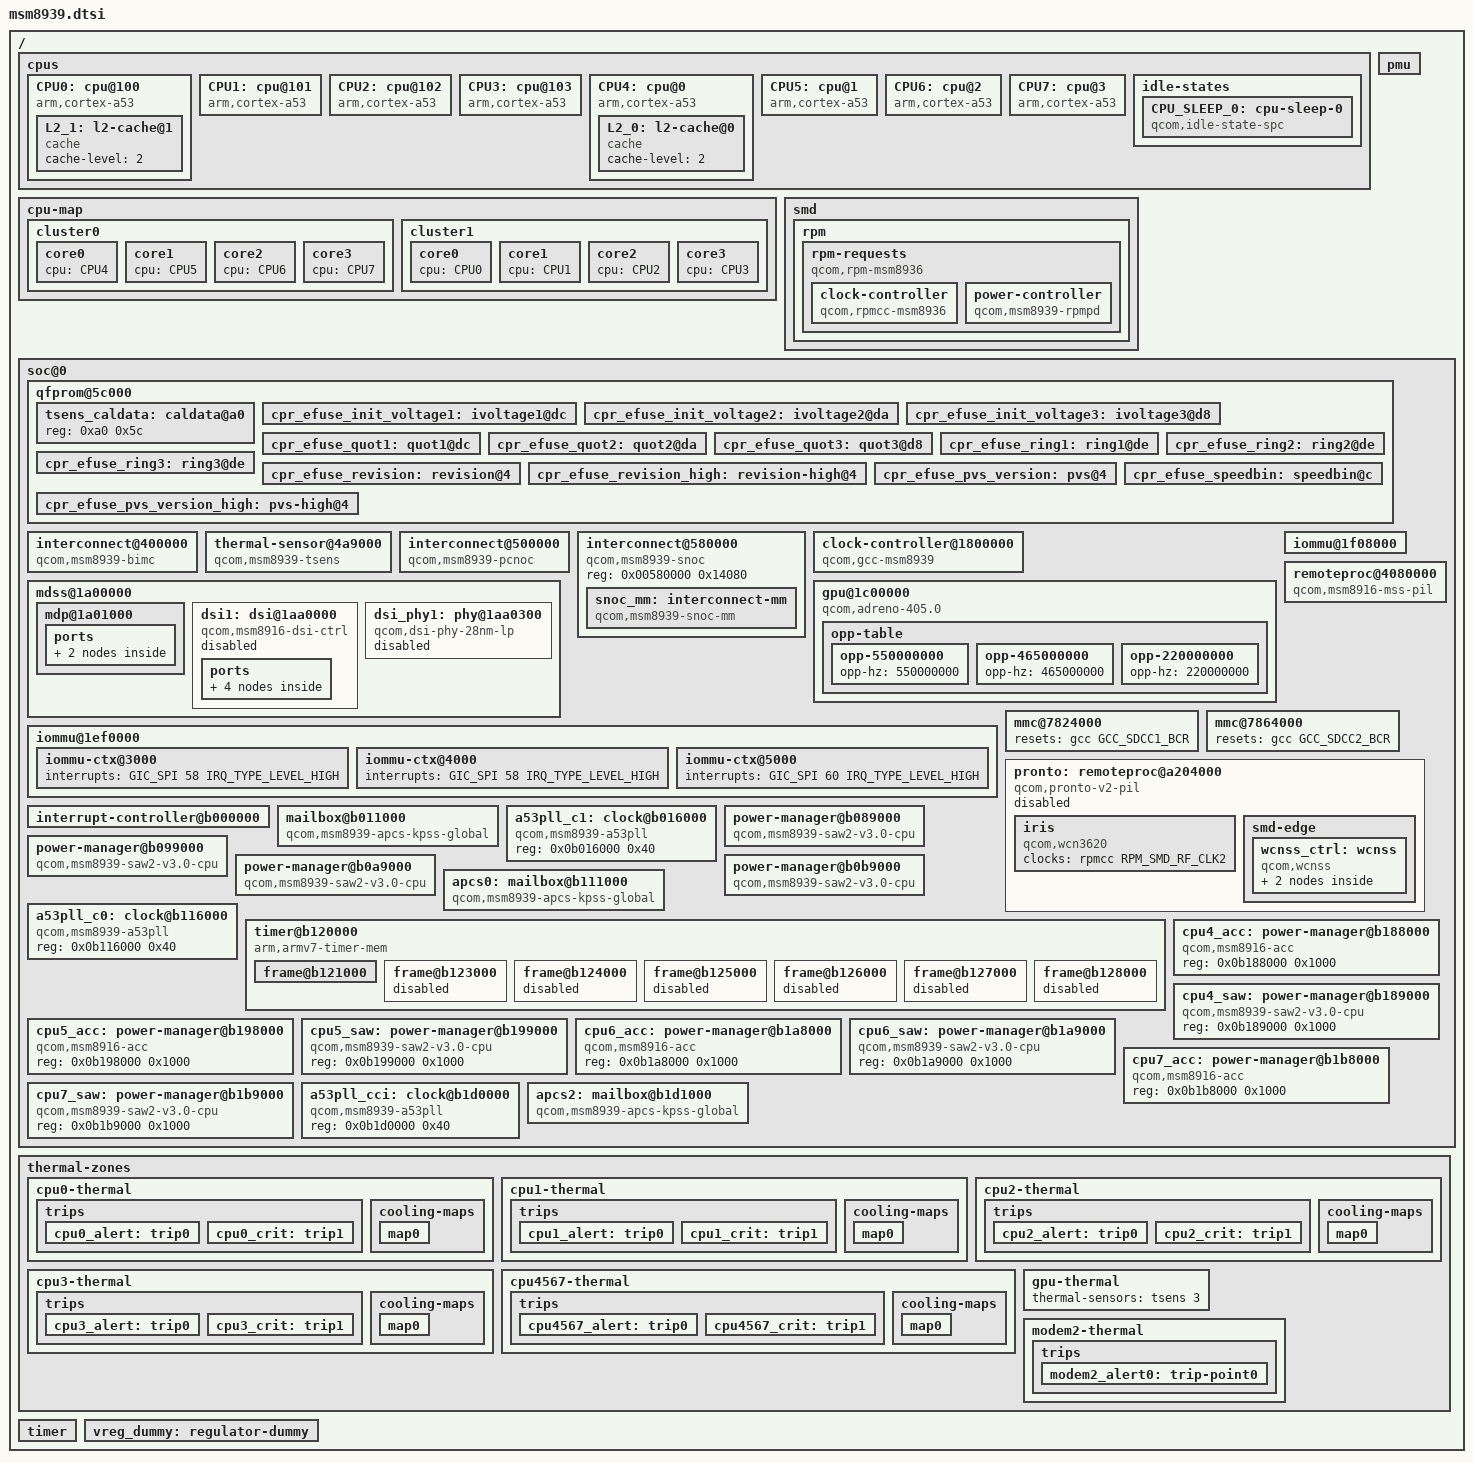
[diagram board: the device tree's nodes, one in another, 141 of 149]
// SPDX-License-Identifier: GPL-2.0-only
/*
 * Copyright (c) 2013-2015, The Linux Foundation. All rights reserved.
 */

#include <dt-bindings/clock/qcom,gcc-msm8939.h>
#include <dt-bindings/interconnect/qcom,msm8939.h>
#include <dt-bindings/reset/qcom,gcc-msm8939.h>

#include "msm8916-common.dtsi"

/ {
	cpus {
		#address-cells = <1>;
		#size-cells = <0>;

		CPU0: cpu@100 {
			device_type = "cpu";
			compatible = "arm,cortex-a53";
			reg = <0x100>;
			next-level-cache = <&L2_1>;
			enable-method = "spin-table";
			clocks = <&apcs>;
			#cooling-cells = <2>;
			power-domains = <&vreg_dummy>;
			power-domain-names = "cpr";
			qcom,acc = <&cpu0_acc>;
			qcom,saw = <&cpu0_saw>;
			cpu-idle-states = <&CPU_SLEEP_0>;

			L2_1: l2-cache@1 {
				compatible = "cache";
				cache-level = <2>;
			};
		};

		CPU1: cpu@101 {
			device_type = "cpu";
			compatible = "arm,cortex-a53";
			reg = <0x101>;
			next-level-cache = <&L2_1>;
			enable-method = "spin-table";
			clocks = <&apcs>;
			#cooling-cells = <2>;
			power-domains = <&vreg_dummy>;
			power-domain-names = "cpr";
			qcom,acc = <&cpu1_acc>;
			qcom,saw = <&cpu1_saw>;
			cpu-idle-states = <&CPU_SLEEP_0>;
		};

		CPU2: cpu@102 {
			device_type = "cpu";
			compatible = "arm,cortex-a53";
			reg = <0x102>;
			next-level-cache = <&L2_1>;
			enable-method = "spin-table";
			clocks = <&apcs>;
			#cooling-cells = <2>;
			power-domains = <&vreg_dummy>;
			power-domain-names = "cpr";
			qcom,acc = <&cpu2_acc>;
			qcom,saw = <&cpu2_saw>;
			cpu-idle-states = <&CPU_SLEEP_0>;
		};

		CPU3: cpu@103 {
			device_type = "cpu";
			compatible = "arm,cortex-a53";
			reg = <0x103>;
			next-level-cache = <&L2_1>;
			enable-method = "spin-table";
			clocks = <&apcs>;
			#cooling-cells = <2>;
			power-domains = <&vreg_dummy>;
			power-domain-names = "cpr";
			qcom,acc = <&cpu3_acc>;
			qcom,saw = <&cpu3_saw>;
			cpu-idle-states = <&CPU_SLEEP_0>;
		};

		CPU4: cpu@0 {
			device_type = "cpu";
			compatible = "arm,cortex-a53";
			reg = <0x0>;
			next-level-cache = <&L2_0>;
			enable-method = "spin-table";
			clocks = <&apcs0>;
			#cooling-cells = <2>;
			power-domains = <&vreg_dummy>;
			power-domain-names = "cpr";
			qcom,acc = <&cpu4_acc>;
			qcom,saw = <&cpu4_saw>;
			cpu-idle-states = <&CPU_SLEEP_0>;

			L2_0: l2-cache@0 {
				compatible = "cache";
				cache-level = <2>;
			};
		};

		CPU5: cpu@1 {
			device_type = "cpu";
			compatible = "arm,cortex-a53";
			reg = <0x1>;
			next-level-cache = <&L2_0>;
			enable-method = "spin-table";
			clocks = <&apcs0>;
			#cooling-cells = <2>;
			power-domains = <&vreg_dummy>;
			power-domain-names = "cpr";
			qcom,acc = <&cpu5_acc>;
			qcom,saw = <&cpu5_saw>;
			cpu-idle-states = <&CPU_SLEEP_0>;
		};

		CPU6: cpu@2 {
			device_type = "cpu";
			compatible = "arm,cortex-a53";
			reg = <0x2>;
			next-level-cache = <&L2_0>;
			enable-method = "spin-table";
			clocks = <&apcs0>;
			#cooling-cells = <2>;
			power-domains = <&vreg_dummy>;
			power-domain-names = "cpr";
			qcom,acc = <&cpu6_acc>;
			qcom,saw = <&cpu6_saw>;
			cpu-idle-states = <&CPU_SLEEP_0>;
		};

		CPU7: cpu@3 {
			device_type = "cpu";
			compatible = "arm,cortex-a53";
			reg = <0x3>;
			next-level-cache = <&L2_0>;
			enable-method = "spin-table";
			clocks = <&apcs0>;
			#cooling-cells = <2>;
			power-domains = <&vreg_dummy>;
			power-domain-names = "cpr";
			qcom,acc = <&cpu7_acc>;
			qcom,saw = <&cpu7_saw>;
			cpu-idle-states = <&CPU_SLEEP_0>;
		};

		idle-states {
			CPU_SLEEP_0: cpu-sleep-0 {
				compatible ="qcom,idle-state-spc", "arm,idle-state";
				entry-latency-us = <130>;
				exit-latency-us = <150>;
				min-residency-us = <2000>;
				local-timer-stop;
			};
		};
	};

	/*
	 * MSM8939 has a big.LITTLE heterogeneous computing architecture,
	 * consisting of two clusters of four ARM Cortex-A53s each. The
	 * LITTLE cluster runs at 1.0-1.2GHz, and the big cluster runs
	 * at 1.5-1.7GHz.
	 *
	 * The enable method used here is spin-table which presupposes use
	 * of a 2nd stage boot shim such as lk2nd to have installed a
	 * spin-table, the downstream non-psci/non-spin-table method that
	 * default msm8916/msm8936/msm8939 will not be supported upstream.
	 */
	cpu-map {
		/* LITTLE (efficiency) cluster */
		cluster0 {
			core0 {
				cpu = <&CPU4>;
			};

			core1 {
				cpu = <&CPU5>;
			};

			core2 {
				cpu = <&CPU6>;
			};

			core3 {
				cpu = <&CPU7>;
			};
		};

		/*
		 * big (performance) cluster
		 * Boot CPU is cluster 1 core 0
		 */
		cluster1 {
			core0 {
				cpu = <&CPU0>;
			};

			core1 {
				cpu = <&CPU1>;
			};

			core2 {
				cpu = <&CPU2>;
			};

			core3 {
				cpu = <&CPU3>;
			};
		};
	};

	pmu {
		interrupts = <GIC_PPI 7 (GIC_CPU_MASK_SIMPLE(8) | IRQ_TYPE_LEVEL_HIGH)>;
	};

	smd {
		rpm {
			rpm-requests {
				compatible = "qcom,rpm-msm8936";

				clock-controller {
					compatible = "qcom,rpmcc-msm8936", "qcom,rpmcc";
				};

				power-controller {
					compatible = "qcom,msm8939-rpmpd";
				};
			};
		};
	};

	soc@0 {
		qfprom@5c000 {
			tsens_caldata: caldata@a0 {
				reg = <0xa0 0x5c>;
			};

			cpr_efuse_init_voltage1: ivoltage1@dc {
				reg = <0xdc 0x4>;
				bits = <4 6>;
			};

			cpr_efuse_init_voltage2: ivoltage2@da {
				reg = <0xda 0x4>;
				bits = <2 6>;
			};

			cpr_efuse_init_voltage3: ivoltage3@d8 {
				reg = <0xd8 0x4>;
				bits = <0 6>;
			};

			cpr_efuse_quot1: quot1@dc {
				reg = <0xdd 0x8>;
				bits = <2 12>;
			};

			cpr_efuse_quot2: quot2@da {
				reg = <0xdb 0x8>;
				bits = <0x0 12>;
			};

			cpr_efuse_quot3: quot3@d8 {
				reg = <0xd8 0x8>;
				bits = <6 12>;
			};

			cpr_efuse_ring1: ring1@de {
				reg = <0xde 0x4>;
				bits = <6 3>;
			};

			cpr_efuse_ring2: ring2@de {
				reg = <0xde 0x4>;
				bits = <6 3>;
			};

			cpr_efuse_ring3: ring3@de {
				reg = <0xde 0x4>;
				bits = <6 3>;
			};

			cpr_efuse_revision: revision@4 {
				reg = <0x5 0x1>;
				bits = <5 1>;
			};

			cpr_efuse_revision_high: revision-high@4 {
				reg = <0x7 0x1>;
				bits = <0 1>;
			};

			cpr_efuse_pvs_version: pvs@4 {
				reg = <0x3 0x1>;
				bits = <5 1>;
			};

			cpr_efuse_pvs_version_high: pvs-high@4 {
				reg = <0x6 0x1>;
				bits = <2 2>;
			};

			cpr_efuse_speedbin: speedbin@c {
				reg = <0xc 0x1>;
				bits = <2 3>;
			};
		};

		interconnect@400000 {
			compatible = "qcom,msm8939-bimc";
		};

		thermal-sensor@4a9000 {
			compatible = "qcom,msm8939-tsens", "qcom,tsens-v0_1";
			nvmem-cells = <&tsens_caldata>;
			nvmem-cell-names = "calib";
			#qcom,sensors = <10>;
		};

		interconnect@500000 {
			compatible = "qcom,msm8939-pcnoc";
		};

		interconnect@580000 {
			compatible = "qcom,msm8939-snoc";
			reg = <0x00580000 0x14080>;

			snoc_mm: interconnect-mm {
				compatible = "qcom,msm8939-snoc-mm";
				clocks = <&rpmcc RPM_SMD_SYSMMNOC_CLK>,
					 <&rpmcc RPM_SMD_SYSMMNOC_A_CLK>;
				clock-names = "bus", "bus_a";
				#interconnect-cells = <1>;
			};
		};

		clock-controller@1800000 {
			compatible = "qcom,gcc-msm8939";
		};

		mdss@1a00000 {
			mdp@1a01000 {
				clocks = <&gcc GCC_MDSS_AHB_CLK>,
					 <&gcc GCC_MDSS_AXI_CLK>,
					 <&gcc GCC_MDSS_MDP_CLK>,
					 <&gcc GCC_MDSS_VSYNC_CLK>,
					 <&gcc GCC_MDP_TBU_CLK>,
					 <&gcc GCC_MDP_RT_TBU_CLK>;
				clock-names = "iface",
					      "bus",
					      "core",
					      "vsync",
					      "tbu",
					      "tbu_rt";

				ports {
					port@1 {
						reg = <1>;

						mdp5_intf2_out: endpoint {
							remote-endpoint = <&dsi1_in>;
						};
					};
				};
			};

			dsi1: dsi@1aa0000 {
				compatible = "qcom,msm8916-dsi-ctrl",
					     "qcom,mdss-dsi-ctrl";
				reg = <0x01aa0000 0x25c>;
				reg-names = "dsi_ctrl";

				interrupt-parent = <&mdss>;
				interrupts = <5>;

				assigned-clocks = <&gcc BYTE1_CLK_SRC>,
						  <&gcc PCLK1_CLK_SRC>;
				assigned-clock-parents = <&dsi_phy1 0>,
							 <&dsi_phy1 1>;

				clocks = <&gcc GCC_MDSS_MDP_CLK>,
					 <&gcc GCC_MDSS_AHB_CLK>,
					 <&gcc GCC_MDSS_AXI_CLK>,
					 <&gcc GCC_MDSS_BYTE1_CLK>,
					 <&gcc GCC_MDSS_PCLK1_CLK>,
					 <&gcc GCC_MDSS_ESC1_CLK>;
				clock-names = "mdp_core",
					      "iface",
					      "bus",
					      "byte",
					      "pixel",
					      "core";
				phys = <&dsi_phy1>;
				status = "disabled";

				ports {
					#address-cells = <1>;
					#size-cells = <0>;

					port@0 {
						reg = <0>;

						dsi1_in: endpoint {
							remote-endpoint = <&mdp5_intf2_out>;
						};
					};

					port@1 {
						reg = <1>;

						dsi1_out: endpoint {
						};
					};
				};
			};

			dsi_phy1: phy@1aa0300 {
				compatible = "qcom,dsi-phy-28nm-lp";
				reg = <0x01aa0300 0xd4>,
				      <0x01aa0500 0x280>,
				      <0x01aa0780 0x30>;
				reg-names = "dsi_pll",
					    "dsi_phy",
					    "dsi_phy_regulator";

				clocks = <&gcc GCC_MDSS_AHB_CLK>,
					 <&xo_board>;
				clock-names = "iface", "ref";

				#clock-cells = <1>;
				#phy-cells = <0>;
				status = "disabled";
			};
		};

		gpu@1c00000 {
			compatible = "qcom,adreno-405.0", "qcom,adreno";
			reg = <0x01c00000 0x10000>;
			reg-names = "kgsl_3d0_reg_memory";
			clocks = <&gcc GCC_OXILI_GFX3D_CLK>,
				 <&gcc GCC_OXILI_AHB_CLK>,
				 <&gcc GCC_OXILI_GMEM_CLK>,
				 <&gcc GCC_BIMC_GFX_CLK>,
				 <&gcc GCC_BIMC_GPU_CLK>,
				 <&gcc GFX3D_CLK_SRC>,
				 <&gcc GCC_OXILI_TIMER_CLK>;
			clock-names = "core",
				      "iface",
				      "mem",
				      "mem_iface",
				      "alt_mem_iface",
				      "gfx3d",
				      "rbbmtimer";

			opp-table {
				opp-550000000 {
					opp-hz = /bits/ 64 <550000000>;
				};

				opp-465000000 {
					opp-hz = /bits/ 64 <465000000>;
				};

				opp-220000000 {
					opp-hz = /bits/ 64 <220000000>;
				};
			};
		};

		iommu@1ef0000 {
			/* VFE */
			iommu-ctx@3000 {
				interrupts = <GIC_SPI 58 IRQ_TYPE_LEVEL_HIGH>;
			};

			/* MDP_0 */
			iommu-ctx@4000 {
				interrupts = <GIC_SPI 58 IRQ_TYPE_LEVEL_HIGH>;
			};

			/* VENUS_NS */
			iommu-ctx@5000 {
				interrupts = <GIC_SPI 60 IRQ_TYPE_LEVEL_HIGH>;
			};
		};

		iommu@1f08000 {
			clocks = <&gcc GCC_SMMU_CFG_CLK>,
				 <&gcc GCC_GFX_TCU_CLK>,
				 <&gcc GCC_GFX_TBU_CLK>;
			clock-names = "iface", "bus", "tbu";
		};

		remoteproc@4080000 {
			compatible = "qcom,msm8916-mss-pil", "qcom,q6v5-pil";
			power-domains = <&rpmpd MSM8939_VDDMDCX>,
					<&rpmpd MSM8939_VDDMX>;
		};

		mmc@7824000 {
			resets = <&gcc GCC_SDCC1_BCR>;
		};

		mmc@7864000 {
			resets = <&gcc GCC_SDCC2_BCR>;
		};

		pronto: remoteproc@a204000 {
			compatible = "qcom,pronto-v2-pil", "qcom,pronto";
			reg = <0x0a204000 0x2000>, <0x0a202000 0x1000>, <0x0a21b000 0x3000>;
			reg-names = "ccu", "dxe", "pmu";

			memory-region = <&wcnss_mem>;

			interrupts-extended = <&intc GIC_SPI 149 IRQ_TYPE_EDGE_RISING>,
					      <&wcnss_smp2p_in 0 IRQ_TYPE_EDGE_RISING>,
					      <&wcnss_smp2p_in 1 IRQ_TYPE_EDGE_RISING>,
					      <&wcnss_smp2p_in 2 IRQ_TYPE_EDGE_RISING>,
					      <&wcnss_smp2p_in 3 IRQ_TYPE_EDGE_RISING>;
			interrupt-names = "wdog", "fatal", "ready", "handover", "stop-ack";

			power-domains = <&rpmpd MSM8939_VDDCX>,
					<&rpmpd MSM8939_VDDMX_AO>;
			power-domain-names = "cx", "mx";

			qcom,smem-states = <&wcnss_smp2p_out 0>;
			qcom,smem-state-names = "stop";

			pinctrl-0 = <&wcnss_pin_a>;
			pinctrl-names = "default";

			status = "disabled";

			iris {
				compatible = "qcom,wcn3620";

				clocks = <&rpmcc RPM_SMD_RF_CLK2>;
				clock-names = "xo";
			};

			smd-edge {
				interrupts = <GIC_SPI 142 IRQ_TYPE_EDGE_RISING>;

				qcom,ipc = <&apcs 8 17>;
				qcom,smd-edge = <6>;
				qcom,remote-pid = <4>;

				label = "pronto";

				wcnss_ctrl: wcnss {
					compatible = "qcom,wcnss";
					qcom,smd-channels = "WCNSS_CTRL";

					qcom,mmio = <&pronto>;

					bluetooth {
						compatible = "qcom,wcnss-bt";
					};

					wifi {
						compatible = "qcom,wcnss-wlan";

						interrupts = <GIC_SPI 145 IRQ_TYPE_LEVEL_HIGH>,
							     <GIC_SPI 146 IRQ_TYPE_LEVEL_HIGH>;
						interrupt-names = "tx", "rx";

						qcom,smem-states = <&apps_smsm 10>, <&apps_smsm 9>;
						qcom,smem-state-names = "tx-enable", "tx-rings-empty";
					};
				};
			};
		};

		interrupt-controller@b000000 {
			interrupts = <GIC_PPI 0 (GIC_CPU_MASK_SIMPLE(8) | IRQ_TYPE_LEVEL_HIGH)>;
		};

		mailbox@b011000 {
			compatible = "qcom,msm8939-apcs-kpss-global", "syscon";
			clocks = <&a53pll_c1>, <&gcc GPLL0_VOTE>, <&xo_board>;
			clock-names = "pll", "aux", "ref";
			assigned-clocks = <&apcs2>;
			assigned-clock-rates = <297600000>;
		};

		a53pll_c1: clock@b016000 {
			compatible = "qcom,msm8939-a53pll";
			reg = <0x0b016000 0x40>;
			#clock-cells = <0>;
		};

		power-manager@b089000 {
			compatible = "qcom,msm8939-saw2-v3.0-cpu", "qcom,saw2";
		};

		power-manager@b099000 {
			compatible = "qcom,msm8939-saw2-v3.0-cpu", "qcom,saw2";
		};

		power-manager@b0a9000 {
			compatible = "qcom,msm8939-saw2-v3.0-cpu", "qcom,saw2";
		};

		power-manager@b0b9000 {
			compatible = "qcom,msm8939-saw2-v3.0-cpu", "qcom,saw2";
		};

		apcs0: mailbox@b111000 {
			compatible = "qcom,msm8939-apcs-kpss-global", "syscon";
			reg = <0x0b111000 0x1000>;
			clocks = <&a53pll_c0>, <&gcc GPLL0_VOTE>, <&xo_board>;
			clock-names = "pll", "aux", "ref";
			#clock-cells = <0>;
			#mbox-cells = <1>;
		};

		a53pll_c0: clock@b116000 {
			compatible = "qcom,msm8939-a53pll";
			reg = <0x0b116000 0x40>;
			#clock-cells = <0>;
		};

		timer@b120000 {
			compatible = "arm,armv7-timer-mem";
			reg = <0x0b120000 0x1000>;
			clock-frequency = <19200000>;
			#address-cells = <1>;
			#size-cells = <1>;
			ranges;

			frame@b121000 {
				frame-number = <0>;
				interrupts = <GIC_SPI 8 IRQ_TYPE_LEVEL_HIGH>,
					     <GIC_SPI 7 IRQ_TYPE_LEVEL_HIGH>;
				reg = <0x0b121000 0x1000>,
				      <0x0b122000 0x1000>;
			};

			frame@b123000 {
				frame-number = <1>;
				interrupts = <GIC_SPI 9 IRQ_TYPE_LEVEL_HIGH>;
				reg = <0x0b123000 0x1000>;
				status = "disabled";
			};

			frame@b124000 {
				frame-number = <2>;
				interrupts = <GIC_SPI 10 IRQ_TYPE_LEVEL_HIGH>;
				reg = <0x0b124000 0x1000>;
				status = "disabled";
			};

			frame@b125000 {
				frame-number = <3>;
				interrupts = <GIC_SPI 11 IRQ_TYPE_LEVEL_HIGH>;
				reg = <0x0b125000 0x1000>;
				status = "disabled";
			};

			frame@b126000 {
				frame-number = <4>;
				interrupts = <GIC_SPI 12 IRQ_TYPE_LEVEL_HIGH>;
				reg = <0x0b126000 0x1000>;
				status = "disabled";
			};

			frame@b127000 {
				frame-number = <5>;
				interrupts = <GIC_SPI 13 IRQ_TYPE_LEVEL_HIGH>;
				reg = <0x0b127000 0x1000>;
				status = "disabled";
			};

			frame@b128000 {
				frame-number = <6>;
				interrupts = <GIC_SPI 14 IRQ_TYPE_LEVEL_HIGH>;
				reg = <0x0b128000 0x1000>;
				status = "disabled";
			};
		};

		cpu4_acc: power-manager@b188000 {
			compatible = "qcom,msm8916-acc";
			reg = <0x0b188000 0x1000>;
		};

		cpu4_saw: power-manager@b189000 {
			compatible = "qcom,msm8939-saw2-v3.0-cpu", "qcom,saw2";
			reg = <0x0b189000 0x1000>;
		};

		cpu5_acc: power-manager@b198000 {
			compatible = "qcom,msm8916-acc";
			reg = <0x0b198000 0x1000>;
		};

		cpu5_saw: power-manager@b199000 {
			compatible = "qcom,msm8939-saw2-v3.0-cpu", "qcom,saw2";
			reg = <0x0b199000 0x1000>;
		};

		cpu6_acc: power-manager@b1a8000 {
			compatible = "qcom,msm8916-acc";
			reg = <0x0b1a8000 0x1000>;
		};

		cpu6_saw: power-manager@b1a9000 {
			compatible = "qcom,msm8939-saw2-v3.0-cpu", "qcom,saw2";
			reg = <0x0b1a9000 0x1000>;
		};

		cpu7_acc: power-manager@b1b8000 {
			compatible = "qcom,msm8916-acc";
			reg = <0x0b1b8000 0x1000>;
		};

		cpu7_saw: power-manager@b1b9000 {
			compatible = "qcom,msm8939-saw2-v3.0-cpu", "qcom,saw2";
			reg = <0x0b1b9000 0x1000>;
		};

		a53pll_cci: clock@b1d0000 {
			compatible = "qcom,msm8939-a53pll";
			reg = <0x0b1d0000 0x40>;
			#clock-cells = <0>;
		};

		apcs2: mailbox@b1d1000 {
			compatible = "qcom,msm8939-apcs-kpss-global", "syscon";
			reg = <0x0b1d1000 0x1000>;
			clocks = <&a53pll_cci>, <&gcc GPLL0_VOTE>, <&xo_board>;
			clock-names = "pll", "aux", "ref";
			#clock-cells = <0>;
			#mbox-cells = <1>;
		};
	};

	thermal-zones {
		cpu0-thermal {
			polling-delay-passive = <250>;
			polling-delay = <1000>;

			thermal-sensors = <&tsens 5>;

			trips {
				cpu0_alert: trip0 {
					temperature = <75000>;
					hysteresis = <2000>;
					type = "passive";
				};

				cpu0_crit: trip1 {
					temperature = <115000>;
					hysteresis = <0>;
					type = "critical";
				};
			};

			cooling-maps {
				map0 {
					trip = <&cpu0_alert>;
					cooling-device = <&CPU0 THERMAL_NO_LIMIT THERMAL_NO_LIMIT>,
							 <&CPU1 THERMAL_NO_LIMIT THERMAL_NO_LIMIT>,
							 <&CPU2 THERMAL_NO_LIMIT THERMAL_NO_LIMIT>,
							 <&CPU3 THERMAL_NO_LIMIT THERMAL_NO_LIMIT>;
				};
			};
		};

		cpu1-thermal {
			polling-delay-passive = <250>;
			polling-delay = <1000>;

			thermal-sensors = <&tsens 6>;

			trips {
				cpu1_alert: trip0 {
					temperature = <75000>;
					hysteresis = <2000>;
					type = "passive";
				};

				cpu1_crit: trip1 {
					temperature = <110000>;
					hysteresis = <2000>;
					type = "critical";
				};
			};

			cooling-maps {
				map0 {
					trip = <&cpu1_alert>;
					cooling-device = <&CPU0 THERMAL_NO_LIMIT THERMAL_NO_LIMIT>,
							 <&CPU1 THERMAL_NO_LIMIT THERMAL_NO_LIMIT>,
							 <&CPU2 THERMAL_NO_LIMIT THERMAL_NO_LIMIT>,
							 <&CPU3 THERMAL_NO_LIMIT THERMAL_NO_LIMIT>;
				};
			};
		};

		cpu2-thermal {
			polling-delay-passive = <250>;
			polling-delay = <1000>;

			thermal-sensors = <&tsens 7>;

			trips {
				cpu2_alert: trip0 {
					temperature = <75000>;
					hysteresis = <2000>;
					type = "passive";
				};

				cpu2_crit: trip1 {
					temperature = <110000>;
					hysteresis = <2000>;
					type = "critical";
				};
			};

			cooling-maps {
				map0 {
					trip = <&cpu2_alert>;
					cooling-device = <&CPU0 THERMAL_NO_LIMIT THERMAL_NO_LIMIT>,
							 <&CPU1 THERMAL_NO_LIMIT THERMAL_NO_LIMIT>,
							 <&CPU2 THERMAL_NO_LIMIT THERMAL_NO_LIMIT>,
							 <&CPU3 THERMAL_NO_LIMIT THERMAL_NO_LIMIT>;
				};
			};
		};

		cpu3-thermal {
			polling-delay-passive = <250>;
			polling-delay = <1000>;

			thermal-sensors = <&tsens 8>;

			trips {
				cpu3_alert: trip0 {
					temperature = <75000>;
					hysteresis = <2000>;
					type = "passive";
				};

				cpu3_crit: trip1 {
					temperature = <110000>;
					hysteresis = <2000>;
					type = "critical";
				};
			};

			cooling-maps {
				map0 {
					trip = <&cpu3_alert>;
					cooling-device = <&CPU0 THERMAL_NO_LIMIT THERMAL_NO_LIMIT>,
							 <&CPU1 THERMAL_NO_LIMIT THERMAL_NO_LIMIT>,
							 <&CPU2 THERMAL_NO_LIMIT THERMAL_NO_LIMIT>,
							 <&CPU3 THERMAL_NO_LIMIT THERMAL_NO_LIMIT>;
				};
			};
		};

		cpu4567-thermal {
			polling-delay-passive = <250>;
			polling-delay = <1000>;

			thermal-sensors = <&tsens 9>;

			trips {
				cpu4567_alert: trip0 {
					temperature = <75000>;
					hysteresis = <2000>;
					type = "passive";
				};

				cpu4567_crit: trip1 {
					temperature = <110000>;
					hysteresis = <2000>;
					type = "critical";
				};
			};

			cooling-maps {
				map0 {
					trip = <&cpu4567_alert>;
					cooling-device = <&CPU4 THERMAL_NO_LIMIT THERMAL_NO_LIMIT>,
							 <&CPU5 THERMAL_NO_LIMIT THERMAL_NO_LIMIT>,
							 <&CPU6 THERMAL_NO_LIMIT THERMAL_NO_LIMIT>,
							 <&CPU7 THERMAL_NO_LIMIT THERMAL_NO_LIMIT>;
				};
			};
		};

		gpu-thermal {
			thermal-sensors = <&tsens 3>;
		};

		modem2-thermal {
			polling-delay-passive = <250>;
			polling-delay = <1000>;

			thermal-sensors = <&tsens 2>;

			trips {
				modem2_alert0: trip-point0 {
					temperature = <85000>;
					hysteresis = <2000>;
					type = "hot";
				};
			};
		};
	};

	timer {
		interrupts = <GIC_PPI 2 (GIC_CPU_MASK_SIMPLE(8) | IRQ_TYPE_LEVEL_LOW)>,
			     <GIC_PPI 3 (GIC_CPU_MASK_SIMPLE(8) | IRQ_TYPE_LEVEL_LOW)>,
			     <GIC_PPI 4 (GIC_CPU_MASK_SIMPLE(8) | IRQ_TYPE_LEVEL_LOW)>,
			     <GIC_PPI 1 (GIC_CPU_MASK_SIMPLE(8) | IRQ_TYPE_LEVEL_LOW)>;
	};

	vreg_dummy: regulator-dummy {
		#power-domain-cells = <0>;
	};
};
